VERSION ""

NS_ :

BS_:

BU_: Display Light Engine

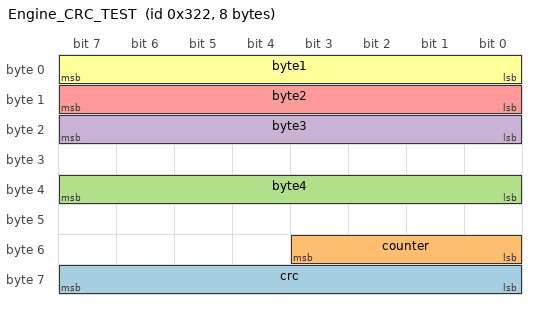
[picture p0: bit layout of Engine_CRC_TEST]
BO_ 802 Engine_CRC_TEST: 8 Engine
 SG_ crc : 63|8@0+ (1,0) [0|255] ""  Display
 SG_ counter : 51|4@0+ (1,0) [0|15] ""  Display
 SG_ byte4 : 39|8@0+ (1,0) [0|0] ""  Display
 SG_ byte3 : 23|8@0+ (1,0) [0|0] ""  Display
 SG_ byte2 : 15|8@0+ (1,0) [0|0] ""  Display
 SG_ byte1 : 7|8@0+ (1,0) [0|0] ""  Display

BO_ 801 LightState: 1 Light
 SG_ HeadLight : 2|1@1+ (1,0) [0|1] ""  Display
 SG_ FlashLight : 0|1@1+ (1,0) [0|1] ""  Display

BO_ 291 EngineState: 2 Engine
 SG_ EngineSpeed : 0|15@1- (1,0) [0|0] ""  Display
 SG_ OnOff : 15|1@1+ (1,0) [0|1] ""  Display

EV_ en_bmw_test: 0 [0|0] "" 0 1 DUMMY_NODE_VECTOR0 Vector__XXX;

BA_DEF_ SG_  "GenSigSendType" ENUM  "Cyclic","OnWrite","OnWriteWithRepetition","OnChange","OnChangeWithRepetition","IfActive","IfActiveWithRepetition";
BA_DEF_ SG_  "GenSigStartValue" FLOAT 0 100000000000;
BA_DEF_ BO_  "GenMsgStartDelayTime" INT 0 100000;
BA_DEF_ BO_  "GenMsgILSupport" ENUM  "No","Yes";
BA_DEF_ BO_  "GenMsgCycleTimeFast" INT 2 100000;
BA_DEF_ BO_  "GenMsgSendType" ENUM  "Cyclic","not_used","not_used","not_used","not_used","Cyclic","not_used","IfActive";
BA_DEF_ BO_  "GenMsgCycleTime" INT 2 50000;
BA_DEF_ BO_  "GenMsgDelayTime" INT 1 1000;
BA_DEF_ BU_  "ILUsed" ENUM  "Yes","No";
BA_DEF_ BU_  "NodeLayerModules" STRING ;
BA_DEF_DEF_  "GenSigSendType" "Cyclic";
BA_DEF_DEF_  "GenSigStartValue" 0;
BA_DEF_DEF_  "GenMsgStartDelayTime" 0;
BA_DEF_DEF_  "GenMsgILSupport" "Yes";
BA_DEF_DEF_  "GenMsgCycleTimeFast" 100;
BA_DEF_DEF_  "GenMsgSendType" "not_used";
BA_DEF_DEF_  "GenMsgCycleTime" 2;
BA_DEF_DEF_  "GenMsgDelayTime" 1;
BA_DEF_DEF_  "ILUsed" "Yes";
BA_DEF_DEF_  "NodeLayerModules" "";
BA_ "GenMsgCycleTime" BO_ 802 50;
BA_ "GenMsgSendType" BO_ 802 0;
BA_ "GenMsgStartDelayTime" BO_ 802 50;
BA_ "GenMsgSendType" BO_ 801 0;
BA_ "GenMsgCycleTime" BO_ 801 100;
BA_ "GenMsgSendType" BO_ 291 0;
BA_ "GenMsgCycleTime" BO_ 291 100;
